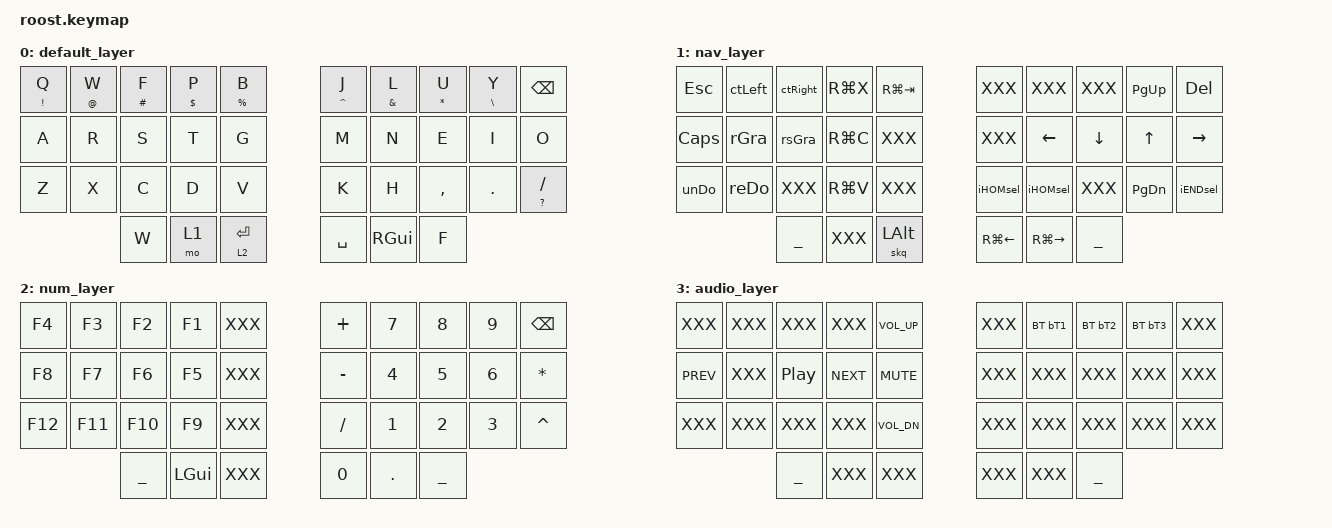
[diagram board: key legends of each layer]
/*
 * Copyright (c) 2021 The ZMK Contributors
 *
 * SPDX-License-Identifier: MIT
 */

#include <behaviors.dtsi>
#include <dt-bindings/zmk/keys.h>
#include <dt-bindings/zmk/bt.h>

/ {
    keymap {
            compatible = "zmk,keymap";
            
    	default_layer {
    		bindings = <
            // ╭─────────────┬─────────────┬─────────────┬─────────────┬─────────────╮   ╭─────────────┬─────────────┬─────────────┬─────────────┬─────────────╮
                 &hm EXCL Q    &hm AT W      &hm HASH F    &hm DLLR P    &hm PRCNT B       &hm CARET J   &hm AMPS L    &hm STAR U    &hm BSLH Y    &kp BSPC 
            // ├─────────────┼─────────────┼─────────────┼─────────────┼─────────────┤   ├─────────────┼─────────────┼─────────────┼─────────────┼─────────────┤
                 &kp A         &kp R         &kp S         &kp T         &kp G             &kp M         &kp N         &kp E         &kp I         &kp O
            // ├─────────────┼─────────────┼─────────────┼─────────────┼─────────────┤   ├─────────────┼─────────────┼─────────────┼─────────────┼─────────────┤
                 &kp Z         &kp X         &kp C         &kp D         &kp V	           &kp K         &kp H         &kp COMMA     &kp DOT       &hm QMARK SLASH
            // ╰─────────────┴─────────────┼─────────────┼─────────────┼─────────────┤   ├─────────────┼─────────────┼─────────────┼─────────────┴─────────────╯
                                             &kp W         &mo  1        &lt 2 RET         &kp SPACE     &kp RGUI      &kp F 
            //                             ╰─────────────┴─────────────┴─────────────╯   ╰─────────────┴─────────────┴─────────────╯
		  >;
        };
		  
        nav_layer {
            bindings = <
            // ╭─────────────┬─────────────┬─────────────┬─────────────┬─────────────╮   ╭─────────────┬─────────────┬─────────────┬─────────────┬─────────────╮
                 &kp ESC       &kp ctLeft    &kp ctRight   &kp RG(X)     &kp RG(TAB)       &kp XXX       &kp XXX       &kp XXX       &kp PG_UP     &kp DEL
            // ├─────────────┼─────────────┼─────────────┼─────────────┼─────────────┤   ├─────────────┼─────────────┼─────────────┼─────────────┼─────────────┤
                 &kp CAPS      &kp rGra      &kp rsGra     &kp RG(C)     &kp XXX           &kp XXX       &kp LEFT      &kp DOWN      &kp UP        &kp RIGHT
            // ├─────────────┼─────────────┼─────────────┼─────────────┼─────────────┤   ├─────────────┼─────────────┼─────────────┼─────────────┼─────────────┤
                 &kp unDo      &kp reDo      &kp XXX       &kp RG(V)     &kp XXX           &kp iHOMsel   &kp iHOMsel   &kp XXX       &kp PG_DN     &kp iENDsel
            // ╰─────────────┴─────────────┼─────────────┼─────────────┼─────────────┤   ├─────────────┼─────────────┼─────────────┼─────────────┴─────────────╯
                                             ___           &kp XXX       &skq LALT         &kp RG(LEFT)  &kp RG(RIGHT) ___
            //                             ╰─────────────┴─────────────┴─────────────╯   ╰─────────────┴─────────────┴─────────────╯
            >;
        };
        
        num_layer {
            bindings = <
            // ╭─────────────┬─────────────┬─────────────┬─────────────┬─────────────╮   ╭─────────────┬─────────────┬─────────────┬─────────────┬─────────────╮
                 &kp F4        &kp F3        &kp F2        &kp F1        &kp XXX           &kp PLUS      &kp N7        &kp N8        &kp N9        &kp BSPC
            // ├─────────────┼─────────────┼─────────────┼─────────────┼─────────────┤   ├─────────────┼─────────────┼─────────────┼─────────────┼─────────────┤
                 &kp F8        &kp F7        &kp F6        &kp F5        &kp XXX           &kp MINUS     &kp N4        &kp N5        &kp N6        &kp STAR 
            // ├─────────────┼─────────────┼─────────────┼─────────────┼─────────────┤   ├─────────────┼─────────────┼─────────────┼─────────────┼─────────────┤
                 &kp F12       &kp F11       &kp F10       &kp F9        &kp XXX           &kp SLASH     &kp N1        &kp N2        &kp N3        &kp CARET
            // ╰─────────────┴─────────────┼─────────────┼─────────────┼─────────────┤   ├─────────────┼─────────────┼─────────────┼─────────────┴─────────────╯
                                             ___           &kp LGUI      &kp XXX           &kp N0        &kp DOT       ___
            //                             ╰─────────────┴─────────────┴─────────────╯   ╰─────────────┴─────────────┴─────────────╯
            >;
        };   

        audio_layer {
            bindings = <
            // ╭─────────────┬─────────────┬─────────────┬─────────────┬─────────────╮   ╭─────────────┬─────────────┬─────────────┬─────────────┬─────────────╮
                 &kp XXX       &kp XXX       &kp XXX       &kp XXX       &kp C_VOL_UP      &kp XXX       &bt bT1       &bt bT2       &bt bT3       &kp XXX
            // ├─────────────┼─────────────┼─────────────┼─────────────┼─────────────┤   ├─────────────┼─────────────┼─────────────┼─────────────┼─────────────┤
                 &kp C_PREV    &kp XXX       &kp C_PP      &kp C_NEXT    &kp K_MUTE        &kp XXX       &kp XXX       &kp XXX       &kp XXX       &kp XXX 
            // ├─────────────┼─────────────┼─────────────┼─────────────┼─────────────┤   ├─────────────┼─────────────┼─────────────┼─────────────┼─────────────┤
                 &kp XXX       &kp XXX       &kp XXX       &kp XXX       &kp C_VOL_DN      &kp XXX       &kp XXX       &kp XXX       &kp XXX       &kp XXX
            // ╰─────────────┴─────────────┼─────────────┼─────────────┼─────────────┤   ├─────────────┼─────────────┼─────────────┼─────────────┴─────────────╯
                                             ___           &kp XXX       &kp XXX           &kp XXX       &kp XXX       ___
            //                             ╰─────────────┴─────────────┴─────────────╯   ╰─────────────┴─────────────┴─────────────╯
            >;
        };   
    };
};
